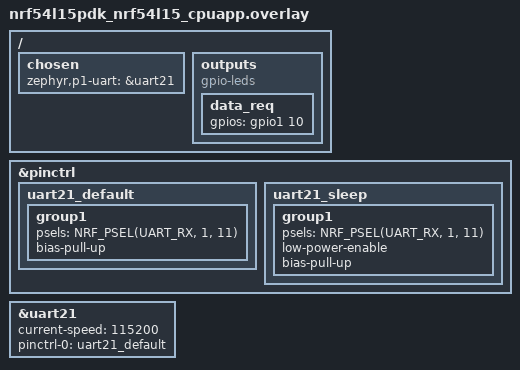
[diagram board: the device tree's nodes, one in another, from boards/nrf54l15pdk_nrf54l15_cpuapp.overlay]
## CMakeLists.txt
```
cmake_minimum_required(VERSION 3.22)

set(CMAKE_EXPORT_COMPILE_COMMANDS ON)
execute_process(
	COMMAND ${CMAKE_COMMAND} -E create_symlink
			${CMAKE_BINARY_DIR}/compile_commands.json compile_commands.json)

list(APPEND ZEPHYR_EXTRA_MODULES ${CMAKE_CURRENT_LIST_DIR}/modules/dsmr_p1)

find_package(Zephyr REQUIRED PATHS $ENV{ZEPHYR_BASE})
project(p1_http_server)

target_sources(app 
    PRIVATE 
        src/main.c
        src/tcp/server.c
        src/http/server.c
        src/http/encoder.c
)

set(gen_dir ${ZEPHYR_BINARY_DIR}/include/generated/)
foreach(web_resource
  index.html
  main.js
  favicon.ico
    )
  generate_inc_file_for_target(
    app
    src/web/${web_resource}
    ${gen_dir}/${web_resource}.gz.inc
    --gzip
  )
endforeach()
```

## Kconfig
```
menu "Zephyr Kernel"
source "Kconfig.zephyr"
endmenu # "Zephyr Kernel"

comment "P1 DSMR HTTP Server"


module = APP
module-str = P1 DSMR HTTP Server
source "subsys/logging/Kconfig.template.log_config"

config ENABLE_WIFI
    bool "Enable WiFi for the Application"
    select WIFI
    select NET_L2_WIFI_MGMT

if WIFI

config WIFI_SSID
    string "SSID of WiFi network"

config WIFI_PSK
    string "Pre-Shared Key of WiFi network"

config WIFI_NXP
    default DT_HAS_NXP_WIFI_ENABLED

config WIFI_AP_SSID
    string "SSID for WiFI access point network"
    default "P1-DMSR-AP"

config WIFI_AP_PSK
    string "PSK for WiFI access point network"
    default "password"

config WIFI_AP_IP_ADDRESS
    string "IP to use in WiFI access point"
    default "192.168.1.1"

config WIFI_AP_NETMASK
    string "Netmask of WiFI access point network"
    default "255.255.255.0"

endif # WIFI
```

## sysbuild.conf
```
SB_CONFIG_BUILD_OUTPUT_HEX=y

SB_CONFIG_BOOTLOADER_MCUBOOT=y
SB_CONFIG_MCUBOOT_MODE_DIRECT_XIP_WITH_REVERT=y
```

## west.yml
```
manifest:
  self:
    west-commands: scripts/west-commands.yml

  remotes:
    - name: zephyr-rtos
      url-base: https://github.com/zephyrproject-rtos

  defaults:
    remote: zephyr-rtos

  projects:
    - name: zephyr
      repo-path: zephyr
      remote: zephyr-rtos
      revision: v4.2.0
      import:
        name-allowlist:
          - zephyr 
          - mcuboot
          - mbedtls
          - hal_espressif
```

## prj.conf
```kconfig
## General
CONFIG_MAIN_THREAD_PRIORITY=7
CONFIG_SYSTEM_WORKQUEUE_STACK_SIZE=2048

CONFIG_WATCHDOG=y

CONFIG_EARLY_CONSOLE=y
CONFIG_INIT_STACKS=y
CONFIG_ERRNO=y
CONFIG_EVENTS=y

CONFIG_SYS_HASH_FUNC32=y
CONFIG_SYS_HASH_MAP=y

CONFIG_JSON_LIBRARY=y

CONFIG_DSMR_P1=y
CONFIG_DSMR_P1_LOG_LEVEL_WRN=y

CONFIG_APP_LOG_LEVEL_INF=y

## DFU
CONFIG_IMG_MANAGER=y
CONFIG_STREAM_FLASH=y
CONFIG_MCUBOOT_SHELL=y


## Persistent Storage
CONFIG_FLASH=y
CONFIG_FLASH_MAP=y
CONFIG_ZMS=y
CONFIG_SETTINGS=y
CONFIG_SETTINGS_ZMS=y


## Networking
CONFIG_NETWORKING=y

CONFIG_NET_TCP=y
CONFIG_NET_UDP=y

CONFIG_NET_DHCPV4=y
CONFIG_NET_DHCPV4_SERVER=y

# CONFIG_NET_TX_STACK_SIZE=2048
# CONFIG_NET_RX_STACK_SIZE=2048

CONFIG_NET_PKT_RX_COUNT=16
CONFIG_NET_PKT_TX_COUNT=16
# CONFIG_NET_BUF_RX_COUNT=20
# CONFIG_NET_BUF_TX_COUNT=20
# CONFIG_NET_MAX_CONTEXTS=10

CONFIG_NET_MAX_CONN=8

CONFIG_NET_SOCKETS=y
CONFIG_NET_SOCKETS_SERVICE_STACK_SIZE=4096

CONFIG_NET_IPV4=y
CONFIG_NET_IPV6=n
CONFIG_NET_IF_MAX_IPV4_COUNT=2
CONFIG_NET_IF_MAX_IPV6_COUNT=2

CONFIG_NET_STATISTICS=y
CONFIG_NET_STATISTICS_PERIODIC_OUTPUT=n

CONFIG_NET_HOSTNAME_ENABLE=y
CONFIG_NET_HOSTNAME="p1-dsmr"

CONFIG_NET_LOG=y
CONFIG_NET_SHELL=y


## WiFi
CONFIG_WIFI=y
CONFIG_WIFI_LOG_LEVEL_ERR=y
CONFIG_NET_L2_WIFI_SHELL=y
CONFIG_WIFI_CREDENTIALS=y
CONFIG_WIFI_CREDENTIALS_BACKEND_SETTINGS=y
CONFIG_WIFI_CREDENTIALS_MAX_ENTRIES=1


## HTTP
CONFIG_HTTP_PARSER=y
CONFIG_HTTP_PARSER_URL=y
CONFIG_HTTP_PARSER_STRICT=y


## Debug 
# Debug optimizations needed to prevent hanging in credential autoconnect in esp32
CONFIG_DEBUG=y
# CONFIG_DEBUG_THREAD_INFO=y
# CONFIG_STACK_USAGE=y
# CONFIG_THREAD_NAME=y
#
# CONFIG_ASSERT=y
# CONFIG_STACK_CANARIES=y
#
# CONFIG_COMPILER_SAVE_TEMPS=y
```

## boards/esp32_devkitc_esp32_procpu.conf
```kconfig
CONFIG_ESP32_WIFI_STA_AUTO_DHCPV4=y
CONFIG_ESP32_WIFI_AP_STA_MODE=y
CONFIG_ESP32_WIFI_STA_SCAN_ALL=y

CONFIG_UART_CONSOLE=y
CONFIG_LOG_BACKEND_UART=y
```

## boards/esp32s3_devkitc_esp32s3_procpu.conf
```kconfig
CONFIG_ENABLE_WIFI=y

CONFIG_ESP32_WIFI_STA_AUTO_DHCPV4=y
CONFIG_ESP32_WIFI_AP_STA_MODE=y
CONFIG_ESP32_WIFI_STA_SCAN_ALL=y

CONFIG_UART_CONSOLE=y
CONFIG_LOG_BACKEND_UART=y
```

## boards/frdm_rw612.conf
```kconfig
CONFIG_ENABLE_WIFI=y
```

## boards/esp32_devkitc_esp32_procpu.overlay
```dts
/ {
    chosen {
        zephyr,p1-uart = &uart2;
    };

    aliases {
        led0 = &led0;
    };

    outputs {
		compatible = "gpio-leds";
		led0: led0 {
			gpios = <&gpio0 23 (GPIO_ACTIVE_HIGH | GPIO_PUSH_PULL)>;
		};
	};
};

&uart2 {
    status = "okay";
    current-speed = <115200>;
};
```

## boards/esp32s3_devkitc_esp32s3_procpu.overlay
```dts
/ {
    chosen {
        zephyr,p1-uart = &uart1;
    };

    aliases {
        led0 = &led0;
    };

    outputs {
		compatible = "gpio-leds";
		led0: led0 {
			gpios = <&gpio0 2 (GPIO_ACTIVE_HIGH | GPIO_PUSH_PULL)>;
		};
	};
};

&uart1 {
    status = "okay";
    current-speed = <115200>;
	pinctrl-0 = <&uart1_default>;
	pinctrl-names = "default";
};

&wifi {
	status = "okay";
};
```

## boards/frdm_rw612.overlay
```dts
/ {
    chosen {
        zephyr,p1-uart = &flexcomm0;
    };
};

&flexcomm0 {
    status = "okay";
};
```

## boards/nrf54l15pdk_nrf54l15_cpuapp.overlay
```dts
/ {
    chosen {
        zephyr,p1-uart = &uart21;
    };

    outputs {
		compatible = "gpio-leds";
		data_req: data_req {
			gpios = <&gpio1 10 (GPIO_ACTIVE_HIGH | GPIO_OPEN_SOURCE)>;
		};
	};
};

&pinctrl {
    uart21_default: uart21_default {
        group1 {
			psels = <NRF_PSEL(UART_RX, 1, 11)>;
            bias-pull-up;
        };
    };
    uart21_sleep: uart21_sleep {
        group1 {
			psels = <NRF_PSEL(UART_RX, 1, 11)>;
			low-power-enable;
            bias-pull-up;
        };
    };
};

uart21: &uart21 {
	current-speed = <115200>;
	status = "okay";
    // parity = "none";
    // stop-bits = "1";
    // data-bits = <8>;
	pinctrl-0 = <&uart21_default>;
	pinctrl-names = "default";
};
```

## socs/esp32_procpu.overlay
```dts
/*
 * Copyright (c) 2022 Espressif Systems (Shanghai) Co., Ltd.
 *
 * SPDX-License-Identifier: Apache-2.0
 */

/ {
	wifi_ap: wifi_ap {
		compatible = "espressif,esp32-wifi";
		status = "okay";
	};
};

&wifi {
	status = "okay";
};
```

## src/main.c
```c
/**
 * @file main.c
 * @author Theis <theismejnertsen@gmail.com>
 * @date 2025-11-02
 */

/******************************************************************************
 * Includes
 *****************************************************************************/

#include "server.h"

#include <dsmr_p1/dsmr_p1.h>

#include <sys/errno.h>
#include <zephyr/app_version.h>
#include <zephyr/data/json.h>
#include <zephyr/drivers/gpio.h>
#include <zephyr/drivers/watchdog.h>
#include <zephyr/kernel.h>
#include <zephyr/logging/log.h>
#include <zephyr/net/dhcpv4_server.h>
#include <zephyr/net/http/status.h>
#include <zephyr/net/wifi.h>
#include <zephyr/net/wifi_credentials.h>
#include <zephyr/net/wifi_mgmt.h>
#include <zephyr/sys/hash_map.h>
#include <zephyr/sys/util.h>
#include <zephyr/toolchain.h>

/******************************************************************************
 * Constants
 *****************************************************************************/

#define NET_MGMT_EVENT_WIFI_SET                                                \
    (NET_EVENT_WIFI_CONNECT_RESULT | NET_EVENT_WIFI_DISCONNECT_RESULT |        \
     NET_EVENT_WIFI_SCAN_RESULT | NET_EVENT_WIFI_SCAN_DONE)

enum main_event {
    MAIN_EVENT_WDT_FEED = BIT(0),
    MAIN_EVENT_DSMR_TELEGRAM_RECEIVED = BIT(1),
    MAIN_EVENT_WIFI_RECONNECT = BIT(2),
    MAIN_EVENT_WIFI_CONFIG_UPDATED = BIT(3),
    MAIN_EVENT_WIFI_AP_ENABLE = BIT(4),
    MAIN_EVENT_WIFI_AP_DISABLE = BIT(5),
};

#define WDT_MAX_WINDOW_MS 60000U
#define WDT_MIN_WINDOW_MS 0U
#define WDT_FEED_TIMEOUT K_MSEC(20000)
#define WDT_OPT WDT_OPT_PAUSE_HALTED_BY_DBG

#define LED_ON_TIME K_MSEC(100)
#define WIFI_AP_DISABLE_TIMEOUT K_MINUTES(2)

static const struct device *wdt = DEVICE_DT_GET(DT_ALIAS(watchdog0));
static const struct gpio_dt_spec led_gpio =
    GPIO_DT_SPEC_GET(DT_ALIAS(led0), gpios);

static const uint8_t index_html_gz[] = {
#include "index.html.gz.inc"
};

static const uint8_t main_js_gz[] = {
#include "main.js.gz.inc"
};

static const uint8_t favicon_ico_gz[] = {
#include "favicon.ico.gz.inc"
};

struct wifi_config {
    char ssid[WIFI_SSID_MAX_LEN];
    char psk[WIFI_PSK_MAX_LEN];
};

struct config {
    struct wifi_config wifi;
};

static const struct json_obj_descr wifi_config_descr[] = {
    JSON_OBJ_DESCR_PRIM(struct wifi_config, ssid, JSON_TOK_STRING_BUF),
    JSON_OBJ_DESCR_PRIM(struct wifi_config, psk, JSON_TOK_STRING_BUF),
};

static const struct json_obj_descr config_descr[] = {
    JSON_OBJ_DESCR_OBJECT(struct config, wifi, wifi_config_descr),
};

/******************************************************************************
 * Private Function Prototypes
 *****************************************************************************/

static int init_wdt(void);
static void wdt_feed_timeout_cb(struct k_timer *timer);
static void led_disable_timeout_cb(struct k_timer *timer);

static void net_mgmt_event_static_handler_cb(uint64_t mgmt_event,
                                             struct net_if *iface, void *info,
                                             size_t info_length,
                                             void *user_data);
static void handle_wifi_connect_result(struct wifi_status *status);
static void wifi_ap_disable_timeout_cb(struct k_timer *timer);
static void wifi_reconnect_timeout_cb(struct k_timer *timer);
static void autoconnect_wifi(void);
static void update_config_from_wifi_cred(void *user_data, const char *ssid,
                                         size_t ssid_len);
static void update_wifi_cred_from_config(void);
static int enable_ap_mode(void);
static int disable_ap_mode(void);
static void enable_dhcpv4_server(struct net_if *iface);
static void disable_dhcpv4_server(struct net_if *iface);

static void apply_config(struct config new, int64_t new_fields_bitmap);

static void telegram_received_cb(const uint8_t *data, size_t len,
                                 void *user_data);

static int resource_handle_index(const struct server_request *req,
                                 struct server_response *res);
static int resource_handle_main_js(const struct server_request *req,
                                   struct server_response *res);
static int resource_handle_favicon(const struct server_request *req,
                                   struct server_response *res);
static int resource_handle_data(const struct server_request *req,
                                struct server_response *res);
static void resource_handle_data_on_done(int err, void *user_data);
static int resource_handle_version(const struct server_request *req,
                                   struct server_response *res);
static int resource_handle_config(const struct server_request *req,
                                  struct server_response *res);
static void resource_handle_config_on_done(int err, void *user_data);

/******************************************************************************
 * Private Variables
 *****************************************************************************/

LOG_MODULE_REGISTER(main, CONFIG_APP_LOG_LEVEL);

static K_EVENT_DEFINE(main_event);

static K_TIMER_DEFINE(wdt_feed_timer, wdt_feed_timeout_cb, NULL);
static K_TIMER_DEFINE(led_disable_timer, led_disable_timeout_cb, NULL);
static K_TIMER_DEFINE(wifi_ap_disable_timer, wifi_ap_disable_timeout_cb, NULL);
static K_TIMER_DEFINE(wifi_reconnect_timer, wifi_reconnect_timeout_cb, NULL);

NET_MGMT_REGISTER_EVENT_HANDLER(wifi_net_mgmt_cb, NET_MGMT_EVENT_WIFI_SET,
                                net_mgmt_event_static_handler_cb, NULL);
static int wdt_channel_id = 0;

static size_t last_telegram_len = 0;
static uint8_t last_telegram[DSMR_P1_TELEGRAM_MAX_SIZE] = {0};
static K_MUTEX_DEFINE(telegram_mu);

static struct config config = {};

static struct net_if *sta_iface = NULL;
static struct net_if *ap_iface = NULL;

/******************************************************************************
 * Public Functions
 *****************************************************************************/

int main(void) {
    int ret;

    ret = init_wdt();
    if (ret < 0) {
        LOG_ERR("failed to init wdt");
        return ret;
    }

    sta_iface = net_if_get_wifi_sta();
    if (!sta_iface) {
        LOG_INF("STA iface: not initialized");
        return -EIO;
    }

    ap_iface = net_if_get_wifi_sap();
    if (!ap_iface) {
        LOG_INF("AP iface: not initialized");
        return -EIO;
    }

    if (!gpio_is_ready_dt(&led_gpio)) {
        LOG_ERR("led0 is not ready");
        return -EIO;
    }
    ret = gpio_pin_configure_dt(&led_gpio, GPIO_OUTPUT_ACTIVE);
    if (ret < 0) {
        LOG_ERR("could not configure led0: %d", ret);
        return ret;
    }

    if (!wifi_credentials_is_empty()) {
        wifi_credentials_for_each_ssid(&update_config_from_wifi_cred, NULL);
    }

    autoconnect_wifi();
    server_add_resource("/", &resource_handle_index);
    server_add_resource("/main.js", &resource_handle_main_js);
    server_add_resource("/favicon.ico", &resource_handle_favicon);
    server_add_resource("/data", &resource_handle_data);
    server_add_resource("/version", &resource_handle_version);
    server_add_resource("/config", &resource_handle_config);
    server_start();

    ret = enable_ap_mode();
    if (ret < 0) {
        LOG_ERR("failed to enable AP: %d", ret);
        return ret;
    }

    ret = dsmr_p1_set_callback(telegram_received_cb, NULL);
    if (ret < 0) {
        LOG_ERR("failed to set dsmr p1 callback: %d", ret);
        return ret;
    }
    ret = dsmr_p1_enable();
    if (ret < 0) {
        LOG_WRN("failed to enable dsmr p1: %d", ret);
    }

    k_timer_start(&wdt_feed_timer, WDT_FEED_TIMEOUT, K_FOREVER);

    uint32_t events;
    while (true) {
        events = k_event_wait(&main_event, UINT32_MAX, true, K_FOREVER);
        LOG_DBG("events: 0x%04x", events);

        if (events & MAIN_EVENT_WDT_FEED) {
            wdt_feed(wdt, wdt_channel_id);
            k_timer_start(&wdt_feed_timer, WDT_FEED_TIMEOUT, K_FOREVER);
        }
        if (events & MAIN_EVENT_DSMR_TELEGRAM_RECEIVED) {
            gpio_pin_set_dt(&led_gpio, 1);
            k_timer_start(&led_disable_timer, LED_ON_TIME, K_FOREVER);
        }
        if (events & MAIN_EVENT_WIFI_RECONNECT) {
            autoconnect_wifi();
        }
        if (events & MAIN_EVENT_WIFI_CONFIG_UPDATED) {
            update_wifi_cred_from_config();
        }
        if (events & MAIN_EVENT_WIFI_AP_ENABLE) {
            enable_ap_mode();
        }
        if (events & MAIN_EVENT_WIFI_AP_DISABLE) {
            disable_ap_mode();
        }
    }

    return 0;
}

/******************************************************************************
 * Private Functions
 *****************************************************************************/

static int init_wdt(void) {
    int ret;
    if (!device_is_ready(wdt)) {
        LOG_ERR("%s: device not ready.\n", wdt->name);
        return -ENODEV;
    }

    struct wdt_timeout_cfg wdt_config = {
        /* Reset SoC when watchdog timer expires. */
        .flags = WDT_FLAG_RESET_SOC,

        /* Expire watchdog after max window */
        .window.min = WDT_MIN_WINDOW_MS,
        .window.max = WDT_MAX_WINDOW_MS,
    };

    ret = wdt_install_timeout(wdt, &wdt_config);
    if (ret < 0) {
        LOG_ERR("Watchdog install error: %d", ret);
        return ret;
    }
    wdt_channel_id = ret;

    ret = wdt_setup(wdt, WDT_OPT);
    if (ret < 0) {
        LOG_ERR("Watchdog setup error: %d", ret);
        return ret;
    }
    return 0;
}

static void wdt_feed_timeout_cb(struct k_timer *timer) {
    ARG_UNUSED(timer);
    k_event_post(&main_event, MAIN_EVENT_WDT_FEED);
}

static void led_disable_timeout_cb(struct k_timer *timer) {
    ARG_UNUSED(timer);
    gpio_pin_set_dt(&led_gpio, 0);
}

static void net_mgmt_event_static_handler_cb(uint64_t mgmt_event,
                                             struct net_if *iface, void *info,
                                             size_t info_length,
                                             void *user_data) {
    ARG_UNUSED(iface);
    ARG_UNUSED(info_length);
    ARG_UNUSED(user_data);
    switch (mgmt_event) {
    case NET_EVENT_WIFI_CONNECT_RESULT:
        handle_wifi_connect_result((struct wifi_status *)info);
        break;

    case NET_EVENT_WIFI_DISCONNECT_RESULT:
        LOG_WRN("wifi disconnected");
        k_timer_start(&wifi_reconnect_timer, K_MSEC(500), K_FOREVER);
        k_event_post(&main_event, MAIN_EVENT_WIFI_AP_ENABLE);
        break;

    default:
        break;
    }
}

static void handle_wifi_connect_result(struct wifi_status *status) {
    if (status->status) {
        LOG_WRN("connection request failed: %d", status->status);
    } else {
        LOG_INF("wifi connected");
        k_timer_start(&wifi_ap_disable_timer, WIFI_AP_DISABLE_TIMEOUT,
                      K_FOREVER);
    }
}

static void wifi_ap_disable_timeout_cb(struct k_timer *timer) {
    ARG_UNUSED(timer);
    k_event_post(&main_event, MAIN_EVENT_WIFI_AP_DISABLE);
}

static void wifi_reconnect_timeout_cb(struct k_timer *timer) {
    ARG_UNUSED(timer);
    k_event_post(&main_event, MAIN_EVENT_WIFI_RECONNECT);
}

static void autoconnect_wifi(void) {
    int ret;
    if (!wifi_credentials_is_empty()) {
        LOG_INF("auto connect wifi");
        ret = net_mgmt(NET_REQUEST_WIFI_CONNECT_STORED, sta_iface, NULL, 0);
        if (ret) {
            LOG_ERR("could not auto-connect to network. %d", ret);
        }
    }
}

static void update_config_from_wifi_cred(void *user_data, const char *ssid,
                                         size_t ssid_len) {
    struct wifi_credentials_personal creds = {};

    memcpy(config.wifi.ssid, ssid, MIN(sizeof(config.wifi.ssid), ssid_len));
    int ret =
        wifi_credentials_get_by_ssid_personal_struct(ssid, ssid_len, &creds);
    if (ret < 0) {
        LOG_ERR("failed to get wifi creds of ssid: %s (%d):", ssid, ret);
        return;
    }
    memcpy(config.wifi.psk, creds.password,
           MIN(sizeof(config.wifi.psk), creds.password_len));
}

static void update_wifi_cred_from_config(void) {
    LOG_INF("wifi credentials updated");
    struct wifi_credentials_personal creds = {};
    memcpy(creds.header.ssid, config.wifi.ssid, sizeof(config.wifi.ssid));
    creds.header.ssid_len = strlen(config.wifi.ssid);

    creds.header.type = WIFI_SECURITY_TYPE_PSK;
    memcpy(creds.password, config.wifi.psk, sizeof(config.wifi.psk));
    creds.password_len = strlen(config.wifi.psk);

    (void)wifi_credentials_delete_all();
    int ret = wifi_credentials_set_personal_struct(&creds);
    if (ret < 0) {
        LOG_ERR("failed to update wifi creds");
    }

    ret = net_mgmt(NET_REQUEST_WIFI_DISCONNECT, sta_iface, NULL, 0);
    if (ret) {
        LOG_WRN("could not disconnect from network. %d", ret);
    }
}

static int enable_ap_mode(void) {
    LOG_INF("Turning on AP Mode");
    static struct wifi_connect_req_params ap_config = {};
    ap_config.ssid = (const uint8_t *)CONFIG_WIFI_AP_SSID;
    ap_config.ssid_length = strlen(CONFIG_WIFI_AP_SSID);
    ap_config.psk = (const uint8_t *)CONFIG_WIFI_AP_PSK;
    ap_config.psk_length = strlen(CONFIG_WIFI_AP_PSK);
    ap_config.channel = WIFI_CHANNEL_ANY;
    ap_config.band = WIFI_FREQ_BAND_2_4_GHZ;

    if (strlen(CONFIG_WIFI_AP_PSK) == 0) {
        ap_config.security = WIFI_SECURITY_TYPE_NONE;
    } else {

        ap_config.security = WIFI_SECURITY_TYPE_PSK;
    }

    enable_dhcpv4_server(ap_iface);

    int ret = net_mgmt(NET_REQUEST_WIFI_AP_ENABLE, ap_iface, &ap_config,
                       sizeof(struct wifi_connect_req_params));
    if (ret) {
        LOG_ERR("NET_REQUEST_WIFI_AP_ENABLE failed, err: %d", ret);
    }

    return ret;
}

static int disable_ap_mode(void) {
    disable_dhcpv4_server(ap_iface);

    int ret = net_mgmt(NET_REQUEST_WIFI_AP_DISABLE, ap_iface, NULL, 0);
    if (ret) {
        LOG_ERR("NET_REQUEST_WIFI_AP_DISABLE failed, err: %d", ret);
    }

    return ret;
}

static void enable_dhcpv4_server(struct net_if *iface) {
    static struct in_addr addr;
    static struct in_addr netmaskAddr;

    __ASSERT(iface != NULL, "null iface");

    if (net_addr_pton(AF_INET, CONFIG_WIFI_AP_IP_ADDRESS, &addr)) {
        LOG_ERR("Invalid address: %s", CONFIG_WIFI_AP_IP_ADDRESS);
        return;
    }

    if (net_addr_pton(AF_INET, CONFIG_WIFI_AP_NETMASK, &netmaskAddr)) {
        LOG_ERR("Invalid netmask: %s", CONFIG_WIFI_AP_NETMASK);
        return;
    }

    net_if_ipv4_set_gw(iface, &addr);

    if (net_if_ipv4_addr_add(iface, &addr, NET_ADDR_MANUAL, 0) == NULL) {
        LOG_ERR("could not set IP address for AP interface");
    }

    if (!net_if_ipv4_set_netmask_by_addr(iface, &addr, &netmaskAddr)) {
        LOG_ERR("could not set netmask for AP interface: %s",
                CONFIG_WIFI_AP_NETMASK);
    }

    addr.s4_addr[3] += 10; /* Starting IPv4 address for DHCPv4 address pool. */

    if (net_dhcpv4_server_start(iface, &addr) != 0) {
        LOG_ERR("DHCP server is not started for desired IP");
        return;
    }

    LOG_INF("DHCPv4 server started...");
}

static void disable_dhcpv4_server(struct net_if *iface) {
    __ASSERT(iface != NULL, "null iface");
    if (net_dhcpv4_server_stop(iface) != 0) {
        LOG_ERR("failed to stop DHCP server");
    }
    LOG_INF("DHCPv4 server stopped...");
}

static void apply_config(struct config new, int64_t new_fields_bitmap) {
    LOG_INF("config update with 0x%llx", new_fields_bitmap);
    if (new_fields_bitmap && BIT(0)) {
        memcpy(config.wifi.ssid, new.wifi.ssid, sizeof(config.wifi.ssid));
        memcpy(config.wifi.psk, new.wifi.psk, sizeof(config.wifi.psk));
        k_event_post(&main_event, MAIN_EVENT_WIFI_CONFIG_UPDATED);
    }
}

static void telegram_received_cb(const uint8_t *data, size_t len,
                                 void *user_data) {
    k_event_post(&main_event, MAIN_EVENT_DSMR_TELEGRAM_RECEIVED);

    int ret = k_mutex_lock(&telegram_mu, K_NO_WAIT);
    if (ret < 0) {
        LOG_ERR("could not lock telegram mutex: %d", ret);
        return;
    }
    last_telegram_len = MIN(len, sizeof(last_telegram));
    memcpy(last_telegram, data, last_telegram_len);
    k_mutex_unlock(&telegram_mu);
}

static int resource_handle_index(const struct server_request *req,
                                 struct server_response *res) {
    if (req->method != HTTP_GET) {
        return -ENOSYS;
    }

    res->status = HTTP_200_OK;
    sys_hashmap_insert(&res->headers, (uint64_t)"Content-Type",
                       (uint64_t)"text/html", NULL);
    sys_hashmap_insert(&res->headers, (uint64_t)"Content-Encoding",
                       (uint64_t)"gzip", NULL);
    res->body = index_html_gz;
    res->body_len = sizeof(index_html_gz);
    return 0;
}

static int resource_handle_main_js(const struct server_request *req,
                                   struct server_response *res) {
    if (req->method != HTTP_GET) {
        return -ENOSYS;
    }

    res->status = HTTP_200_OK;
    sys_hashmap_insert(&res->headers, (uint64_t)"Content-Type",
                       (uint64_t)"text/javascript", NULL);
    sys_hashmap_insert(&res->headers, (uint64_t)"Content-Encoding",
                       (uint64_t)"gzip", NULL);
    res->body = main_js_gz;
    res->body_len = sizeof(index_html_gz);
    return 0;
}

static int resource_handle_favicon(const struct server_request *req,
                                   struct server_response *res) {
    if (req->method != HTTP_GET) {
        return -ENOSYS;
    }

    res->status = HTTP_200_OK;
    sys_hashmap_insert(&res->headers, (uint64_t)"Content-Type",
                       (uint64_t)"image/svg+xml", NULL);
    sys_hashmap_insert(&res->headers, (uint64_t)"Content-Encoding",
                       (uint64_t)"gzip", NULL);
    res->body = favicon_ico_gz;
    res->body_len = sizeof(favicon_ico_gz);
    return 0;
}

static int resource_handle_data(const struct server_request *req,
                                struct server_response *res) {
    if (req->method != HTTP_GET) {
        res->status = HTTP_405_METHOD_NOT_ALLOWED;
        return 0;
    }

    int ret = k_mutex_lock(&telegram_mu, K_FOREVER);
    if (ret < 0) {
        return ret;
    }

    res->status = HTTP_200_OK;
    sys_hashmap_insert(&res->headers, (uint64_t)"Content-Type",
                       (uint64_t)"text/plain", NULL);
    res->body = last_telegram;
    res->body_len = last_telegram_len;
    res->on_done = resource_handle_data_on_done;
    return 0;
}

static void resource_handle_data_on_done(int err, void *user_data) {
    ARG_UNUSED(err);
    ARG_UNUSED(user_data);
    k_mutex_unlock(&telegram_mu);
}

static int resource_handle_version(const struct server_request *req,
                                   struct server_response *res) {
    if (req->method != HTTP_GET) {
        res->status = HTTP_405_METHOD_NOT_ALLOWED;
        return 0;
    }

    res->status = HTTP_200_OK;
    res->body = APP_VERSION_STRING;
    res->body_len = sizeof(APP_VERSION_STRING) - 1;
    return 0;
}

static int resource_handle_config(const struct server_request *req,
                                  struct server_response *res) {
    int ret;
    size_t payload_len = 1024;
    uint8_t *payload = malloc(payload_len);
    if (!payload) {
        LOG_ERR("failed to allocate response");
        return -ENOMEM;
    }
    memset(payload, 0, payload_len);

    res->status = HTTP_200_OK;
    res->body = payload;
    res->body_len = 0;
    res->on_done = &resource_handle_config_on_done;
    res->user_data = payload;

    struct config new_config;
    switch (req->method) {
    case HTTP_GET:
        sys_hashmap_insert(&res->headers, (uint64_t)"Content-Type",
                           (uint64_t)"application/json", NULL);
        ret = json_obj_encode_buf(config_descr, ARRAY_SIZE(config_descr),
                                  &config, payload, payload_len - 1);
        if (ret < 0) {
            LOG_ERR("failed to encode payload: %d", ret);
            return ret;
        }
        res->body_len = strlen(payload);
        break;
    case HTTP_POST:
        ret = json_obj_parse((char *)req->body, req->body_len, config_descr,
                             ARRAY_SIZE(config_descr), &new_config);
        if (ret < 0) {
            res->status = HTTP_400_BAD_REQUEST;
            LOG_ERR("failed to decode payload: %d", ret);
            break;
        }
        LOG_INF("new config SSID: %s PSK: %s", new_config.wifi.ssid,
                new_config.wifi.psk);
        apply_config(new_config, ret);
        break;
    default:
        res->status = HTTP_405_METHOD_NOT_ALLOWED;
        break;
    }

    return 0;
}

static void resource_handle_config_on_done(int err, void *user_data) {
    ARG_UNUSED(err);
    free(user_data);
}
```

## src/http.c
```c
#include "http.h"

#include <errno.h>
#include <stdio.h>
#include <string.h>

#define HTTP_PROTOCOL "HTTP/1.1"
#define HTTP_DELIM "\r\n"

static const char http_protocol[] = HTTP_PROTOCOL;
static const char http_delim[] = HTTP_DELIM;

static int append_delim(http_encoder_ctx_t *ctx) {
    int ret =
        snprintf(&ctx->buf[ctx->offs], ctx->len - ctx->offs, "%s", http_delim);
    if (ret < 0) {
        return -ENOMEM;
    }
    ctx->offs += ret;
    return 0;
}

int http_encoder_init(http_encoder_ctx_t *ctx, char *buf, size_t len,
                      enum http_status status) {
    if (ctx == NULL || buf == NULL || len == 0) {
        return -EINVAL;
    }
    if (len < (sizeof(http_protocol) - 1) + 4 + (sizeof(http_delim) - 1)) {
        return -ENOMEM;
    }
    memset(ctx, 0, sizeof(*ctx));
    ctx->buf = buf;
    ctx->len = len;
    memset(ctx->buf, 0, len);
    int ret = snprintf(ctx->buf, ctx->len, "%s %d%s", http_protocol, status,
                       http_delim);
    if (ret < 0) {
        return -ENOMEM;
    }
    ctx->offs = ret;
    return 0;
}

int http_encoder_set_body_marker(http_encoder_ctx_t *ctx) {
    return append_delim(ctx);
}

int http_encoder_append(http_encoder_ctx_t *ctx, const char *data, size_t len) {
    if ((ctx->len - ctx->offs) < len) {
        return -ENOMEM;
    }
    memcpy(&ctx->buf[ctx->offs], data, len);
    ctx->offs += len;
    return 0;
}

int http_encoder_append_header(http_encoder_ctx_t *ctx, const char *key,
                                            const char *value) {
    int ret =
        snprintf(&ctx->buf[ctx->offs], ctx->len - ctx->offs, "%s:%s", key, value);
    if (ret < 0) {
        return -ENOMEM;
    }
    ctx->offs += ret;
    return append_delim(ctx);
}

int http_encoder_append_header_content_type(http_encoder_ctx_t *ctx,
                                            const char *content_type) {
    return http_encoder_append_header(ctx, "ContentType", content_type);
}

int http_encoder_append_header_location(http_encoder_ctx_t *ctx,
                                        const char *location) {
    return http_encoder_append_header(ctx, "Location", location);
}
```

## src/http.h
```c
#ifndef _SRC_HTTP_H__
#define _SRC_HTTP_H__

#include <zephyr/kernel.h>
#include <zephyr/net/http/status.h>

typedef struct {
    char *buf;
    size_t len;
    size_t offs;
} http_encoder_ctx_t;

int http_encoder_init(http_encoder_ctx_t *ctx, char *buf, size_t len,
                      enum http_status status);
int http_encoder_set_body_marker(http_encoder_ctx_t *ctx);
int http_encoder_append(http_encoder_ctx_t *ctx, const char *data, size_t len);
int http_encoder_append_header(http_encoder_ctx_t *ctx, const char *key,
                               const char *value);
int http_encoder_append_header_content_type(http_encoder_ctx_t *ctx,
                                            const char *content_type);
int http_encoder_append_header_location(http_encoder_ctx_t *ctx,
                                        const char *location);

#endif // _SRC_HTTP_H__
```

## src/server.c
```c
/**
 * @file server.c
 * @author Theis <theismejnertsen@gmail.com>
 * @date 2025-11-02
 */

/******************************************************************************
 * Includes
 *****************************************************************************/

#include "server.h"
#include "http.h"
#include "zephyr/net/http/status.h"
#include <errno.h>
#include <string.h>
#include <zephyr/kernel.h>
#include <zephyr/net/http/method.h>
#include <zephyr/net/http/parser.h>
#include <zephyr/net/net_ip.h>
#include <zephyr/net/socket.h>
#include <zephyr/net/wifi_credentials.h>
#include <zephyr/net/wifi_mgmt.h>
#include <zephyr/sys/errno_private.h>
#include <zephyr/sys/hash_map.h>
#include <zephyr/toolchain.h>

#include <zephyr/logging/log.h>

/******************************************************************************
 * Constants
 *****************************************************************************/

#define STATUS_STR_LEN 3
#define HTTP_DELIM "\r\n";

// Just incase response cannot be serialized, use this string
static const char http_insufficient_storage[] =
    "HTTP/1.1 507 Insufficient Storage\r\n\r\n";

/******************************************************************************
 * Local Function Prototypes
 *****************************************************************************/

static int setup_server_socket(void);
static void server_thread(void);
static void handle_client(int fd, const struct sockaddr_in addr,
                          const socklen_t addrlen);

static int handle_url_cb(struct http_parser *, const char *at, size_t length);
static int handle_body_cb(struct http_parser *, const char *at, size_t length);
static void route_request(const struct server_request *req,
                          struct server_response *res);
static int serialize_response(const struct server_response *res, uint8_t *buf,
                              size_t len);
static void serialize_response_append_header(uint64_t key, uint64_t value,
                                             void *cookie);
static enum http_status errno_to_http_status(int err);

/******************************************************************************
 * Private Variables
 *****************************************************************************/

LOG_MODULE_REGISTER(server, CONFIG_APP_LOG_LEVEL);

static int server_fd = -1;
static uint8_t rx_buf[16384] = {0};
static uint8_t tx_buf[8192] = {0};

BUILD_ASSERT(
    sizeof(tx_buf) > sizeof(http_insufficient_storage),
    "tx_buf must be larger than the insufficient storage backup message");

K_SEM_DEFINE(server_run_sem, 0, 1);
K_THREAD_DEFINE(http_server, 8192, server_thread, NULL, NULL, NULL, 2, 0, 0);
struct server_request request;

SYS_HASHMAP_DEFINE_STATIC(resource_map);

/******************************************************************************
 * Public Functions
 *****************************************************************************/

void server_start(void) { k_sem_give(&server_run_sem); }

void server_stop(void) {
    k_sem_reset(&server_run_sem);
    if (server_fd >= 0) {
        (void)zsock_close(server_fd);
    }
}

int server_add_resource(char *uri, server_resource_cb_t cb) {
    int ret;
    uint64_t key = (uint64_t)sys_hash32(uri, strnlen(uri, 128));
    LOG_DBG("resource: uri: %s, key: %llu", uri, key);
    if (sys_hashmap_contains_key(&resource_map, key)) {
        return -EALREADY;
    }

    ret = sys_hashmap_insert(&resource_map, key, (uint64_t)cb, NULL);
    if (ret < 0) {
        return ret;
    }
    return 0;
}

int server_remove_resource(char *uri) {
    uint64_t key = (uint64_t)sys_hash32(uri, 128);

    // For idempotency, dont care if map was deleted or not found
    (void)sys_hashmap_remove(&resource_map, key, NULL);
    return 0;
}

/******************************************************************************
 * Local Function Implementation
 *****************************************************************************/

static int setup_server_socket(void) {
    int ret;
    struct sockaddr_in addr = {
        .sin_port = htons(80),
        .sin_family = AF_INET,
    };
    socklen_t addrlen = sizeof(addr);

    int fd = zsock_socket(addr.sin_family, SOCK_STREAM, IPPROTO_TCP);
    if (fd < 0) {
        ret = -*z_errno();
        LOG_ERR("could not get socket: %d", ret);
        return ret;
    }

    ret = zsock_bind(fd, (struct sockaddr *)&addr, addrlen);
    if (ret) {
        ret = -*z_errno();
        LOG_ERR("could not bind to socket: %d", ret);
        goto server_close;
    }

    ret = zsock_listen(fd, 5);
    if (ret) {
        ret = -*z_errno();
        LOG_ERR("could not listen to socket: %d", ret);
        goto server_close;
    }

    return fd;

server_close:
    (void)zsock_close(fd);
    return ret;
}

static void server_thread(void) {
    int ret;
    server_fd = setup_server_socket();
    if (server_fd < 0) {
        return;
    }

    int client_fd = -1;
    struct sockaddr_in client_addr = {};
    socklen_t client_addrlen = sizeof(client_addr);
    while (true) {
        ret = k_sem_take(&server_run_sem, K_FOREVER);
        if (ret < 0) {
            LOG_ERR("could not take server run sem: %d", ret);
            goto server_close;
        }

        while (true) {
            LOG_INF("waiting for client");
            client_fd = zsock_accept(server_fd, (struct sockaddr *)&client_addr,
                                     &client_addrlen);
            if (client_fd < 0) {
                ret = -*z_errno();
                LOG_WRN("could not accept client: %d", ret);
                break;
            }

            handle_client(client_fd, client_addr, client_addrlen);

            (void)zsock_close(client_fd);
            LOG_INF("client closed");
        }
    }

server_close:
    LOG_INF("server closed");
    (void)zsock_close(server_fd);
    return;
}

static void handle_client(int fd, const struct sockaddr_in addr,
                          const socklen_t addrlen) {
    int ret;
    memset(rx_buf, 0, sizeof(rx_buf));
    ret = zsock_recv(fd, rx_buf, sizeof(rx_buf), 0);
    if (ret < 0) {
        ret = -*z_errno();
        LOG_ERR("could not receive from client: %d", ret);
        return;
    }
    size_t rx_len = (size_t)ret;

    static char addr_str[128] = {0};
    char *dst = net_addr_ntop(addr.sin_family, &addr.sin_addr, addr_str,
                              sizeof(addr_str));
    if (dst != NULL) {
        LOG_INF("received %dB from %s", ret, addr_str);
    }
    LOG_HEXDUMP_INF(rx_buf, rx_len, "data:");

    memset(&request, 0, sizeof(request));
    struct http_parser parser = {};
    struct http_parser_settings settings = {
        .on_url = handle_url_cb,
        .on_body = handle_body_cb,
    };
    http_parser_init(&parser, HTTP_REQUEST);
    http_parser_execute(&parser, &settings, rx_buf, rx_len);
    request.method = parser.method;

    LOG_DBG("%d http request on %s", parser.method, request.url);
    LOG_HEXDUMP_DBG(request.body, request.body_len, "request body");

    SYS_HASHMAP_DEFINE_STATIC(headers_map);
    sys_hashmap_clear(&headers_map, NULL, NULL);

    struct server_response response = {};
    response.headers = headers_map;
    route_request(&request, &response);
    ret = serialize_response(&response, tx_buf, sizeof(tx_buf));
    if (ret < 0) {
        LOG_ERR("failed to serialize response: %d", ret);
        return;
    }

    size_t tx_len = ret;
    LOG_HEXDUMP_DBG(tx_buf, tx_len, "response:");
    zsock_send(fd, tx_buf, tx_len, 0);
    if (response.on_done) {
        response.on_done(ret, response.user_data);
    }
}

static int handle_url_cb(struct http_parser *parser, const char *at,
                         size_t length) {
    ARG_UNUSED(parser);
    if (length >= sizeof(request.url)) {
        return -E2BIG;
    }
    memcpy(request.url, at, length);
    return 0;
}

static int handle_body_cb(struct http_parser *parser, const char *at,
                          size_t length) {
    ARG_UNUSED(parser);
    request.body = (const uint8_t *)at;
    request.body_len = length;
    return 0;
}

static void route_request(const struct server_request *req,
                          struct server_response *res) {
    uint64_t key = (uint64_t)sys_hash32(req->url, strnlen(req->url, 128));

    LOG_DBG("uri: %s, key: %llu", req->url, key);
    server_resource_cb_t resource_cb;
    if (!sys_hashmap_get(&resource_map, key, (uint64_t *)&resource_cb)) {
        res->status = HTTP_404_NOT_FOUND;
        return;
    }

    int ret = resource_cb(req, res);
    if (ret < 0) {
        sys_hashmap_clear(&res->headers, NULL, NULL);
        res->body = NULL;
        res->body_len = 0;
        res->status = errno_to_http_status(ret);
    }
}

static int serialize_response(const struct server_response *res, uint8_t *buf,
                              size_t len) {
    http_encoder_ctx_t ctx = {};
    int ret = http_encoder_init(&ctx, buf, len, res->status);
    if (ret < 0) {
        return ret;
    }

    if (!sys_hashmap_is_empty(&res->headers)) {
        sys_hashmap_foreach(&res->headers, serialize_response_append_header,
                            &ctx);
    }

    if (!res->body || !res->body_len) {
        return ctx.offs;
    }

    ret = http_encoder_set_body_marker(&ctx);
    if (ret < 0) {
        return ret;
    }

    ret = http_encoder_append(&ctx, res->body, res->body_len);
    if (ret < 0) {
        return ret;
    }

    return ctx.offs;
}

static void serialize_response_append_header(uint64_t key, uint64_t value,
                                             void *cookie) {
    http_encoder_ctx_t *ctx = cookie;
    LOG_DBG("Header: %s:%s", (char *)key, (char *)value);
    int ret = http_encoder_append_header(ctx, (char *)key, (char *)value);
    if (ret < 0) {
        LOG_ERR("could not parse header: %d", ret);
    }
}

static enum http_status errno_to_http_status(int err) {
    err = abs(err);

    switch (err) {
    case -EINVAL:
        return HTTP_400_BAD_REQUEST;
    case -ENOSYS:
        return HTTP_501_NOT_IMPLEMENTED;
    default:
        return HTTP_500_INTERNAL_SERVER_ERROR;
    }
}
```

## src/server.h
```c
/**
 * @file server.h
 * @author Theis <theismejnertsen@gmail.com>
 * @date 2025-11-02
 */

#ifndef __SERVER_H__
#define __SERVER_H__

/******************************************************************************
 * Includes
 *****************************************************************************/

#include "zephyr/sys/hash_map.h"
#include <stddef.h>
#include <zephyr/net/http/method.h>
#include <zephyr/net/http/status.h>

/******************************************************************************
 * Constants
 *****************************************************************************/

#define SERVER_URL_MAX_LEN 128

/******************************************************************************
 * Types
 *****************************************************************************/

struct server_request {
    char url[SERVER_URL_MAX_LEN];
    enum http_method method;
    const char *body;
    size_t body_len;
};

struct server_response {
    int status;
    struct sys_hashmap headers;
    char *body;
    size_t body_len;
    void (*on_done)(int err, void *user_data);
    void *user_data; // Data to be passed into callbacks
};

typedef int (*server_resource_cb_t)(const struct server_request *req,
                                    struct server_response *res);

/******************************************************************************
 * Functions
 *****************************************************************************/

/**
 * Start the HTTP server
 */
void server_start(void);

/**
 * Stop the HTTP server
 */
void server_stop(void);

int server_add_resource(char *uri, server_resource_cb_t cb);

int server_remove_resource(char *uri);

#endif // __SERVER_H__
```
